# STM32F302 register map
File version: 1.8
CPU: CM4 r1p0, little endian, MPU, FPU, 4 interrupt priority bits
Registers are 32-bit, read-write, reset 0x0 unless marked. A register's access mark holds for its fields unless they carry their own. Offsets are from the block's base; [hi:lo] are bit positions; {n}, {i} and the like mark numbered series.

## USB — Universal serial bus full-speed device interface
Base 0x40005C00
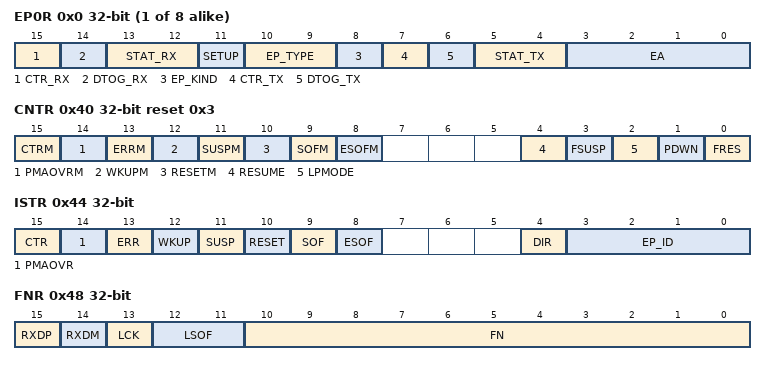
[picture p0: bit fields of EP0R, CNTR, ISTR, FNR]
{0x0+4i} EP{i}R (i=0..7) access per field — endpoint {i} register
  [15] CTR_RX rw write-0-clears — Correct transfer for reception
  [14] DTOG_RX rw write-1-toggles — Data Toggle, for reception transfers
  [13:12] STAT_RX rw write-1-toggles — Status bits, for reception transfers
    on read: 0=Disabled (all reception requests addressed to this endpoint are ignored); 1=Stall (the endpoint is stalled and all reception requests result in a STALL handshake); 2=Nak (the endpoint is naked and all reception requests result in a NAK handshake); 3=Valid (this endpoint is enabled for reception)
  [11] SETUP ro — Setup transaction completed
  [10:9] EP_TYPE rw — Endpoint type
    0=Bulk endpoint; 1=Control endpoint; 2=Iso (Iso endpoint); 3=Interrupt endpoint
  [8] EP_KIND rw — Endpoint kind
  [7] CTR_TX rw write-0-clears — Correct Transfer for transmission
  [6] DTOG_TX rw write-1-toggles — Data Toggle, for transmission transfers
  [5:4] STAT_TX rw write-1-toggles — Status bits, for transmission transfers
    on read: 0=Disabled (all transmission requests addressed to this endpoint are ignored); 1=Stall (the endpoint is stalled and all transmission requests result in a STALL handshake); 2=Nak (the endpoint is naked and all transmission requests result in a NAK handshake); 3=Valid (this endpoint is enabled for transmission)
  [3:0] EA rw — Endpoint address
0x40 CNTR reset 0x3 — control register
  [15] CTRM — Correct transfer interrupt mask
    0=Disabled (Correct Transfer (CTR) Interrupt disabled); 1=Enabled (CTR Interrupt enabled, an interrupt request is generated when the corresponding bit in the USB_ISTR register is set)
  [14] PMAOVRM — Packet memory area over / underrun interrupt mask
    0=Disabled (PMAOVR Interrupt disabled); 1=Enabled (PMAOVR Interrupt enabled, an interrupt request is generated when the corresponding bit in the USB_ISTR register is set)
  [13] ERRM — Error interrupt mask
    0=Disabled (ERR Interrupt disabled); 1=Enabled (ERR Interrupt enabled, an interrupt request is generated when the corresponding bit in the USB_ISTR register is set)
  [12] WKUPM — Wakeup interrupt mask
    0=Disabled (WKUP Interrupt disabled); 1=Enabled (WKUP Interrupt enabled, an interrupt request is generated when the corresponding bit in the USB_ISTR register is set)
  [11] SUSPM — Suspend mode interrupt mask
    0=Disabled (Suspend Mode Request SUSP Interrupt disabled); 1=Enabled (SUSP Interrupt enabled, an interrupt request is generated when the corresponding bit in the USB_ISTR register is set)
  [10] RESETM — USB reset interrupt mask
    0=Disabled (RESET Interrupt disabled); 1=Enabled (RESET Interrupt enabled, an interrupt request is generated when the corresponding bit in the USB_ISTR register is set)
  [9] SOFM — Start of frame interrupt mask
    0=Disabled (SOF Interrupt disabled); 1=Enabled (SOF Interrupt enabled, an interrupt request is generated when the corresponding bit in the USB_ISTR register is set)
  [8] ESOFM — Expected start of frame interrupt mask
    0=Disabled (ESOF Interrupt disabled); 1=Enabled (ESOF Interrupt enabled, an interrupt request is generated when the corresponding bit in the USB_ISTR register is set)
  [4] RESUME — Resume request
    1=Requested (Resume requested)
  [3] FSUSP — Force suspend
    0=NoEffect; 1=Suspend (Enter suspend mode. Clocks and static power dissipation in the analog transceiver are left unaffected)
  [2] LPMODE — Low-power mode
    0=Disabled (No low-power mode); 1=Enabled (Enter low-power mode)
  [1] PDWN — Power down
    0=Disabled (No power down); 1=Enabled (Enter power down mode)
  [0] FRES — Force USB Reset
    0=NoReset (Clear USB reset); 1=Reset (Force a reset of the USB peripheral, exactly like a RESET signaling on the USB)
0x44 ISTR access per field — interrupt status register
  [15] CTR ro — Correct transfer
    1=Completed (Endpoint has successfully completed a transaction)
  [14] PMAOVR rw write-0-clears — Packet memory area over / underrun
    on read: 0=NotOverrun (Overrun is not occurred); 1=Overrun (Microcontroller has not been able to respond in time to an USB memory request) | on write: 0=Clear flag
  [13] ERR rw write-0-clears — Error
    on read: 0=NotOverrun (Errors are not occurred); 1=Error (One of No ANSwer, Cyclic Redundancy Check, Bit Stuffing or Framing format Violation error occurred) | on write: 0=Clear flag
  [12] WKUP rw write-0-clears — Wakeup
    on read: 0=NotWakeup; 1=Wakeup (Activity is detected that wakes up the USB peripheral) | on write: 0=Clear flag
  [11] SUSP rw write-0-clears — Suspend mode request
    on read: 0=NotSuspend; 1=Suspend (No traffic has been received for 3 ms, indicating a suspend mode request from the USB bus) | on write: 0=Clear flag
  [10] RESET rw write-0-clears — reset request
    on read: 0=NotReset; 1=Reset (Peripheral detects an active USB RESET signal at its inputs) | on write: 0=Clear flag
  [9] SOF rw write-0-clears — start of frame
    on read: 0=NotStartOfFrame; 1=StartOfFrame (Beginning of a new USB frame and it is set when a SOF packet arrives through the USB bus) | on write: 0=Clear flag
  [8] ESOF rw write-0-clears — Expected start frame
    on read: 0=NotExpectedStartOfFrame; 1=ExpectedStartOfFrame (An SOF packet is expected but not received) | on write: 0=Clear flag
  [4] DIR ro — Direction of transaction
    0=To (Data transmitted by the USB peripheral to the host PC); 1=From (Data received by the USB peripheral from the host PC)
  [3:0] EP_ID ro — Endpoint Identifier
0x48 FNR ro — frame number register
  [15] RXDP — Receive data + line status
    1=received data plus upstream port data line
  [14] RXDM — Receive data - line status
    1=received data minus upstream port data line
  [13] LCK — Locked
    1=Locked (the frame timer remains in this state until an USB reset or USB suspend event occurs)
  [12:11] LSOF — Lost SOF
  [10:0] FN — Frame number
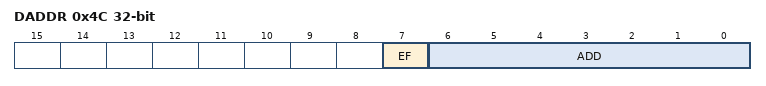
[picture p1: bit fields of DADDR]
0x4C DADDR — device address
  [7] EF — Enable function
    0=Disabled (USB device disabled); 1=Enabled (USB device enabled)
  [6:0] ADD — Device address
0x50 BTABLE — Buffer table address
  [15:3] BTABLE — Buffer table
